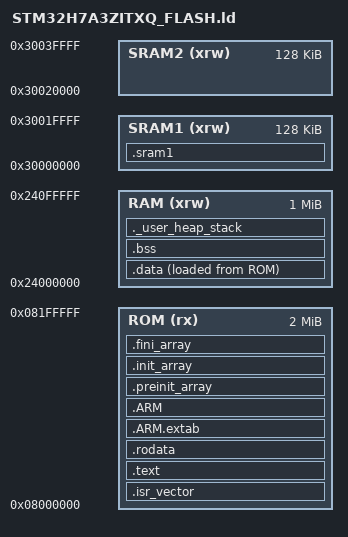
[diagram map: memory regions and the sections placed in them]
/*
******************************************************************************
**
**  File        : LinkerScript.ld
**
**  Author		: Auto-generated by STM32CubeIDE
**
**  Abstract    : Linker script for STM32H7A3ZITxQ Device from STM32H7 series
**                      2048Kbytes ROM
**                      1024Kbytes RAM
**
**                Set heap size, stack size and stack location according
**                to application requirements.
**
**                Set memory bank area and size if external memory is used.
**
**  Target      : STMicroelectronics STM32
**
**  Distribution: The file is distributed as is without any warranty
**                of any kind.
**
*****************************************************************************
** @attention
**
** <h2><center>&copy; COPYRIGHT(c) 2019 STMicroelectronics</center></h2>
**
** Redistribution and use in source and binary forms, with or without modification,
** are permitted provided that the following conditions are met:
**   1. Redistributions of source code must retain the above copyright notice,
**      this list of conditions and the following disclaimer.
**   2. Redistributions in binary form must reproduce the above copyright notice,
**      this list of conditions and the following disclaimer in the documentation
**      and/or other materials provided with the distribution.
**   3. Neither the name of STMicroelectronics nor the names of its contributors
**      may be used to endorse or promote products derived from this software
**      without specific prior written permission.
**
** THIS SOFTWARE IS PROVIDED BY THE COPYRIGHT HOLDERS AND CONTRIBUTORS "AS IS"
** AND ANY EXPRESS OR IMPLIED WARRANTIES, INCLUDING, BUT NOT LIMITED TO, THE
** IMPLIED WARRANTIES OF MERCHANTABILITY AND FITNESS FOR A PARTICULAR PURPOSE ARE
** DISCLAIMED. IN NO EVENT SHALL THE COPYRIGHT HOLDER OR CONTRIBUTORS BE LIABLE
** FOR ANY DIRECT, INDIRECT, INCIDENTAL, SPECIAL, EXEMPLARY, OR CONSEQUENTIAL
** DAMAGES (INCLUDING, BUT NOT LIMITED TO, PROCUREMENT OF SUBSTITUTE GOODS OR
** SERVICES; LOSS OF USE, DATA, OR PROFITS; OR BUSINESS INTERRUPTION) HOWEVER
** CAUSED AND ON ANY THEORY OF LIABILITY, WHETHER IN CONTRACT, STRICT LIABILITY,
** OR TORT (INCLUDING NEGLIGENCE OR OTHERWISE) ARISING IN ANY WAY OUT OF THE USE
** OF THIS SOFTWARE, EVEN IF ADVISED OF THE POSSIBILITY OF SUCH DAMAGE.
**
*****************************************************************************
*/

/* Entry Point */
ENTRY(Reset_Handler)

/* Highest address of the user mode stack */
_estack = ORIGIN(RAM) + LENGTH(RAM);

_Min_Heap_Size = 0x200;
_Min_Stack_Size = 0x1000;

/* Memories definition */
MEMORY
{
  ROM    (rx)     : ORIGIN = 0x08000000, LENGTH = 2048K
  RAM    (xrw)    : ORIGIN = 0x24000000, LENGTH = 1024K
  SRAM1  (xrw)    : ORIGIN = 0x30000000, LENGTH = 128K
  SRAM2  (xrw)    : ORIGIN = 0x30020000, LENGTH = 128K
}

/* Sections */
SECTIONS
{
  .isr_vector :
  {
    . = ALIGN(4);
    KEEP(*(.isr_vector))
    . = ALIGN(4);
  } >ROM

  .text :
  {
    . = ALIGN(4);
    *(.text)
    *(.text*)
    *(.glue_7)
    *(.glue_7t)
    *(.eh_frame)
    KEEP (*(.init))
    KEEP (*(.fini))
    . = ALIGN(4);
    _etext = .;
  } >ROM

  .rodata :
  {
    . = ALIGN(4);
    *(.rodata)
    *(.rodata*)
    . = ALIGN(4);
  } >ROM

  .ARM.extab (READONLY) :
  {
    . = ALIGN(4);
    *(.ARM.extab* .gnu.linkonce.armextab.*)
    . = ALIGN(4);
  } >ROM

  .ARM (READONLY) :
  {
    . = ALIGN(4);
    __exidx_start = .;
    *(.ARM.exidx*)
    __exidx_end = .;
    . = ALIGN(4);
  } >ROM

  .preinit_array (READONLY) :
  {
    . = ALIGN(4);
    PROVIDE_HIDDEN (__preinit_array_start = .);
    KEEP (*(.preinit_array*))
    PROVIDE_HIDDEN (__preinit_array_end = .);
    . = ALIGN(4);
  } >ROM

  .init_array (READONLY) :
  {
    . = ALIGN(4);
    PROVIDE_HIDDEN (__init_array_start = .);
    KEEP (*(SORT(.init_array.*)))
    KEEP (*(.init_array*))
    PROVIDE_HIDDEN (__init_array_end = .);
    . = ALIGN(4);
  } >ROM

  .fini_array (READONLY) :
  {
    . = ALIGN(4);
    PROVIDE_HIDDEN (__fini_array_start = .);
    KEEP (*(SORT(.fini_array.*)))
    KEEP (*(.fini_array*))
    PROVIDE_HIDDEN (__fini_array_end = .);
    . = ALIGN(4);
  } >ROM

  _sidata = LOADADDR(.data);

  .data :
  {
    . = ALIGN(4);
    _sdata = .;
    *(.data)
    *(.data*)
    . = ALIGN(4);
    _edata = .;
  } >RAM AT> ROM

  . = ALIGN(4);
  .bss :
  {
    _sbss = .;
    __bss_start__ = _sbss;
    *(.bss)
    *(.bss*)
    *(COMMON)
    . = ALIGN(4);
    _ebss = .;
    __bss_end__ = _ebss;
  } >RAM

  /* ====== DMA буферы в SRAM1 ====== */
  .sram1 (NOLOAD) :
  {
    . = ALIGN(4);
    *(.sram1)
    *(.sram1*)
    . = ALIGN(4);
  } >SRAM1

  ._user_heap_stack :
  {
    . = ALIGN(8);
    PROVIDE ( end = . );
    PROVIDE ( _end = . );
    . = . + _Min_Heap_Size;
    . = . + _Min_Stack_Size;
    . = ALIGN(8);
  } >RAM

  /DISCARD/ :
  {
    libc.a ( * )
    libm.a ( * )
    libgcc.a ( * )
  }

  .ARM.attributes 0 : { *(.ARM.attributes) }
}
